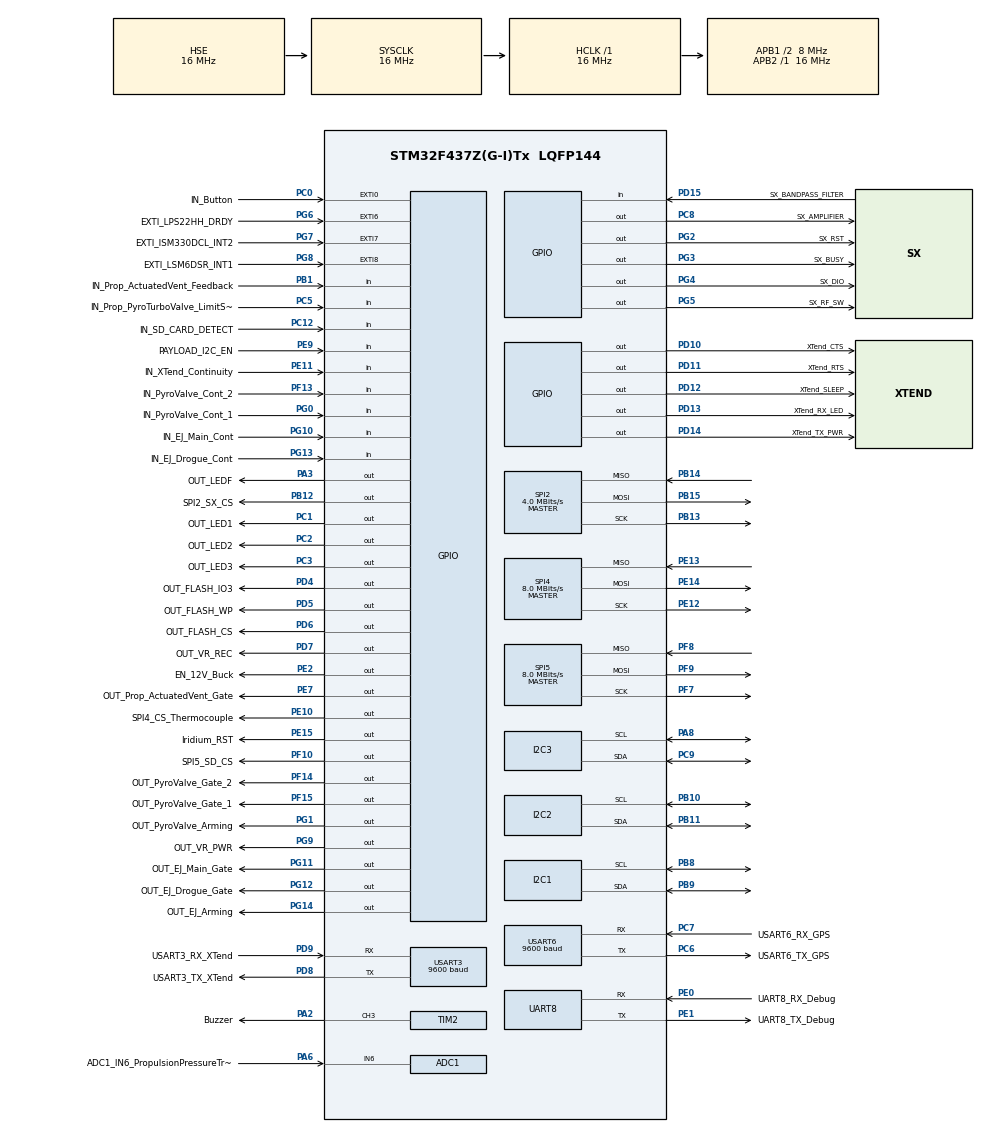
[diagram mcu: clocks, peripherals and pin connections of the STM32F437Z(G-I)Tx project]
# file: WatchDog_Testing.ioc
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ADC1.Channel-0\#ChannelRegularConversion=ADC_CHANNEL_6
ADC1.NbrOfConversionFlag=1
ADC1.Rank-0\#ChannelRegularConversion=1
ADC1.SamplingTime-0\#ChannelRegularConversion=ADC_SAMPLETIME_3CYCLES
ADC1.master=1
FREERTOS.Mutexes01=MEMORY,Dynamic,NULL;TELEMETRY,Dynamic,NULL;SENSOR_POLLING,Dynamic,NULL
FREERTOS.Tasks01=Memory0,48,512,StartMemory0,Default,NULL,Dynamic,NULL,NULL;Ejection1,32,512,StartEjection1,Default,NULL,Dynamic,NULL,NULL;Telemetry2,40,512,StartTelemetry2,Default,NULL,Dynamic,NULL,NULL;Sensors3,24,512,StartSensors3,Default,NULL,Dynamic,NULL,NULL;Propulsion4,48,512,StartPropulsion4,Default,NULL,Dynamic,NULL,NULL;Printing,8,512,StartPrinting,Default,NULL,Dynamic,NULL,NULL
FREERTOS.configUSE_NEWLIB_REENTRANT=1
IWDG.Prescaler=IWDG_PRESCALER_64
IWDG.Reload=2499
Mcu.Family=STM32F4
Mcu.Name=STM32F437Z(G-I)Tx
Mcu.Package=LQFP144
NVIC.EXTI0_IRQn=true\:5\:0\:false\:false\:true\:true\:true\:true
NVIC.PriorityGroup=NVIC_PRIORITYGROUP_4
NVIC.RTC_Alarm_IRQn=true\:5\:0\:false\:false\:true\:false\:true\:true
NVIC.TIM6_DAC_IRQn=true\:0\:0\:false\:false\:true\:false\:false\:true
NVIC.TimeBase=TIM6_DAC_IRQn
NVIC.TimeBaseIP=TIM6
PA13.Mode=Trace_Asynchronous_SW
PA13.Signal=SYS_JTMS-SWDIO
PA14.Mode=Trace_Asynchronous_SW
PA14.Signal=SYS_JTCK-SWCLK
PA2.GPIO_Label=Buzzer
PA2.Signal=S_TIM2_CH3
PA3.GPIO_Label=OUT_LEDF
PA3.Signal=GPIO_Output
PA6.GPIO_Label=ADC1_IN6_PropulsionPressureTransducer
PA6.Signal=ADCx_IN6
PA8.GPIO_Pu=GPIO_PULLUP
PA8.Mode=I2C
PA8.Signal=I2C3_SCL
PB1.GPIO_Label=IN_Prop_ActuatedVent_Feedback
PB1.Signal=GPIO_Input
PB10.GPIO_Pu=GPIO_PULLUP
PB10.Mode=I2C
PB10.Signal=I2C2_SCL
PB11.GPIO_Pu=GPIO_PULLUP
PB11.Mode=I2C
PB11.Signal=I2C2_SDA
PB12.GPIO_Label=SPI2_SX_CS
PB12.Signal=GPIO_Output
PB13.Mode=Full_Duplex_Master
PB13.Signal=SPI2_SCK
PB14.Mode=Full_Duplex_Master
PB14.Signal=SPI2_MISO
PB15.Mode=Full_Duplex_Master
PB15.Signal=SPI2_MOSI
PB3.Mode=Trace_Asynchronous_SW
PB3.Signal=SYS_JTDO-SWO
PB8.GPIO_Pu=GPIO_PULLUP
PB8.Mode=I2C
PB8.Signal=I2C1_SCL
PB9.GPIO_Pu=GPIO_PULLUP
PB9.Mode=I2C
PB9.Signal=I2C1_SDA
PC0.GPIO_Label=IN_Button
PC0.GPIO_ModeDefaultEXTI=GPIO_MODE_IT_FALLING
PC0.Signal=GPXTI0
PC1.GPIO_Label=OUT_LED1
PC1.Signal=GPIO_Output
PC12.GPIO_Label=IN_SD_CARD_DETECT
PC12.Signal=GPIO_Input
PC14/OSC32_IN.Mode=LSE-External-Oscillator
PC14/OSC32_IN.Signal=RCC_OSC32_IN
PC15/OSC32_OUT.Mode=LSE-External-Oscillator
PC15/OSC32_OUT.Signal=RCC_OSC32_OUT
PC2.GPIO_Label=OUT_LED2
PC2.Signal=GPIO_Output
PC3.GPIO_Label=OUT_LED3
PC3.Signal=GPIO_Output
PC5.GPIO_Label=IN_Prop_PyroTurboValve_LimitSwitch
PC5.Signal=GPIO_Input
PC6.GPIO_Label=USART6_TX_GPS
PC6.Mode=Asynchronous
PC6.Signal=USART6_TX
PC7.GPIO_Label=USART6_RX_GPS
PC7.Mode=Asynchronous
PC7.Signal=USART6_RX
PC8.GPIO_Label=SX_AMPLIFIER
PC8.Signal=GPIO_Output
PC9.GPIO_Pu=GPIO_PULLUP
PC9.Mode=I2C
PC9.Signal=I2C3_SDA
PD10.GPIO_Label=XTend_CTS
PD10.Signal=GPIO_Output
PD11.GPIO_Label=XTend_RTS
PD11.Signal=GPIO_Output
PD12.GPIO_Label=XTend_SLEEP
PD12.Signal=GPIO_Output
PD13.GPIO_Label=XTend_RX_LED
PD13.Signal=GPIO_Output
PD14.GPIO_Label=XTend_TX_PWR
PD14.Signal=GPIO_Output
PD15.GPIO_Label=SX_BANDPASS_FILTER
PD15.Signal=GPIO_Input
PD4.GPIO_Label=OUT_FLASH_IO3
PD4.Signal=GPIO_Output
PD5.GPIO_Label=OUT_FLASH_WP
PD5.Signal=GPIO_Output
PD6.GPIO_Label=OUT_FLASH_CS
PD6.Signal=GPIO_Output
PD7.GPIO_Label=OUT_VR_REC
PD7.Signal=GPIO_Output
PD8.GPIO_Label=USART3_TX_XTend
PD8.Mode=Asynchronous
PD8.Signal=USART3_TX
PD9.GPIO_Label=USART3_RX_XTend
PD9.Mode=Asynchronous
PD9.Signal=USART3_RX
PE0.GPIO_Label=UART8_RX_Debug
PE0.Mode=Asynchronous
PE0.Signal=UART8_RX
PE1.GPIO_Label=UART8_TX_Debug
PE1.Mode=Asynchronous
PE1.Signal=UART8_TX
PE10.GPIO_Label=SPI4_CS_Thermocouple
PE10.Signal=GPIO_Output
PE11.GPIO_Label=IN_XTend_Continuity
PE11.Signal=GPIO_Input
PE12.Mode=Full_Duplex_Master
PE12.Signal=SPI4_SCK
PE13.Mode=Full_Duplex_Master
PE13.Signal=SPI4_MISO
PE14.Mode=Full_Duplex_Master
PE14.Signal=SPI4_MOSI
PE15.GPIO_Label=Iridium_RST
PE15.Signal=GPIO_Output
PE2.GPIO_Label=EN_12V_Buck
PE2.Signal=GPIO_Output
PE7.GPIO_Label=OUT_Prop_ActuatedVent_Gate
PE7.Signal=GPIO_Output
PE9.GPIO_Label=PAYLOAD_I2C_EN
PE9.Signal=GPIO_Input
PF10.GPIO_Label=SPI5_SD_CS
PF10.Signal=GPIO_Output
PF13.GPIO_Label=IN_PyroValve_Cont_2
PF13.Signal=GPIO_Input
PF14.GPIO_Label=OUT_PyroValve_Gate_2
PF14.Signal=GPIO_Output
PF15.GPIO_Label=OUT_PyroValve_Gate_1
PF15.Signal=GPIO_Output
PF7.Mode=Full_Duplex_Master
PF7.Signal=SPI5_SCK
PF8.Mode=Full_Duplex_Master
PF8.Signal=SPI5_MISO
PF9.Mode=Full_Duplex_Master
PF9.Signal=SPI5_MOSI
PG0.GPIO_Label=IN_PyroValve_Cont_1
PG0.Signal=GPIO_Input
PG1.GPIO_Label=OUT_PyroValve_Arming
PG1.Signal=GPIO_Output
PG10.GPIO_Label=IN_EJ_Main_Cont
PG10.Signal=GPIO_Input
PG11.GPIO_Label=OUT_EJ_Main_Gate
PG11.Signal=GPIO_Output
PG12.GPIO_Label=OUT_EJ_Drogue_Gate
PG12.Signal=GPIO_Output
PG13.GPIO_Label=IN_EJ_Drogue_Cont
PG13.Signal=GPIO_Input
PG14.GPIO_Label=OUT_EJ_Arming
PG14.Signal=GPIO_Output
PG2.GPIO_Label=SX_RST
PG2.Signal=GPIO_Output
PG3.GPIO_Label=SX_BUSY
PG3.Signal=GPIO_Output
PG4.GPIO_Label=SX_DIO
PG4.Signal=GPIO_Output
PG5.GPIO_Label=SX_RF_SW
PG5.Signal=GPIO_Output
PG6.GPIO_Label=EXTI_LPS22HH_DRDY
PG6.Signal=GPXTI6
PG7.GPIO_Label=EXTI_ISM330DCL_INT2
PG7.Signal=GPXTI7
PG8.GPIO_Label=EXTI_LSM6DSR_INT1
PG8.Signal=GPXTI8
PG9.GPIO_Label=OUT_VR_PWR
PG9.Signal=GPIO_Output
PH0/OSC_IN.Mode=HSE-External-Oscillator
PH0/OSC_IN.Signal=RCC_OSC_IN
PH1/OSC_OUT.Mode=HSE-External-Oscillator
PH1/OSC_OUT.Signal=RCC_OSC_OUT
ProjectManager.HeapSize=0x600
ProjectManager.StackSize=0x400
ProjectManager.TargetToolchain=STM32CubeIDE
RCC.48MHZClocksFreq_Value=48000000
RCC.AHBFreq_Value=16000000
RCC.APB1CLKDivider=RCC_HCLK_DIV2
RCC.APB1Freq_Value=8000000
RCC.APB1TimFreq_Value=16000000
RCC.APB2Freq_Value=16000000
RCC.APB2TimFreq_Value=16000000
RCC.CortexFreq_Value=16000000
RCC.HCLKFreq_Value=16000000
RCC.HSE_VALUE=16000000
RCC.HSI_VALUE=16000000
RCC.PLLM=8
RCC.PLLN=72
RCC.PLLQ=3
RCC.PLLSourceVirtual=RCC_PLLSOURCE_HSE
RCC.SYSCLKFreq_VALUE=16000000
RCC.SYSCLKSource=RCC_SYSCLKSOURCE_HSE
RCC.VCOOutputFreq_Value=144000000
RTC.Alarm=RTC_ALARM_A
RTC.Minutes_A=1
SH.ADCx_IN6.0=ADC1_IN6,IN6
SH.S_TIM2_CH3.0=TIM2_CH3,PWM Generation3 CH3
SPI2.BaudRatePrescaler=SPI_BAUDRATEPRESCALER_2
SPI2.CalculateBaudRate=4.0 MBits/s
SPI2.Direction=SPI_DIRECTION_2LINES
SPI2.Mode=SPI_MODE_MASTER
SPI2.VirtualType=VM_MASTER
SPI4.BaudRatePrescaler=SPI_BAUDRATEPRESCALER_2
SPI4.CalculateBaudRate=8.0 MBits/s
SPI4.Direction=SPI_DIRECTION_2LINES
SPI4.Mode=SPI_MODE_MASTER
SPI4.VirtualType=VM_MASTER
SPI5.BaudRatePrescaler=SPI_BAUDRATEPRESCALER_2
SPI5.CalculateBaudRate=8.0 MBits/s
SPI5.Direction=SPI_DIRECTION_2LINES
SPI5.Mode=SPI_MODE_MASTER
SPI5.VirtualType=VM_MASTER
TIM2.Channel-PWM\ Generation3\ CH3=TIM_CHANNEL_3
UART8.VirtualMode=Asynchronous
USART3.BaudRate=9600
USART3.VirtualMode=VM_ASYNC
USART6.BaudRate=9600
USART6.VirtualMode=VM_ASYNC
VP_FREERTOS_VS_CMSIS_V2.Mode=CMSIS_V2
VP_IWDG_VS_IWDG.Mode=IWDG_Activate
VP_RTC_VS_RTC_Activate.Mode=RTC_Enabled
VP_RTC_VS_RTC_Alarm_A_Intern.Mode=Alarm A
VP_RTC_VS_RTC_Calendar.Mode=RTC_Calendar
VP_SYS_VS_tim6.Mode=TIM6
board=custom

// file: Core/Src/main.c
/* USER CODE BEGIN Header */
/**
  ******************************************************************************
  * @file           : main.c
  * @brief          : Main program body
  ******************************************************************************
  * @attention
  *
  * <h2><center>&copy; Copyright (c) 2022 STMicroelectronics.
  * All rights reserved.</center></h2>
  *
  * This software component is licensed by ST under Ultimate Liberty license
  * SLA0044, the "License"; You may not use this file except in compliance with
  * the License. You may obtain a copy of the License at:
  *                             www.st.com/SLA0044
  *
  ******************************************************************************
  */
/* USER CODE END Header */
#include "main.h"
#include "cmsis_os.h"

/* USER CODE BEGIN Includes */

#include <string.h>
#include <MRT_Helpers.h>

/* USER CODE END Includes */

ADC_HandleTypeDef hadc1;

I2C_HandleTypeDef hi2c1;
I2C_HandleTypeDef hi2c2;
I2C_HandleTypeDef hi2c3;

IWDG_HandleTypeDef hiwdg;

RTC_HandleTypeDef hrtc;

SPI_HandleTypeDef hspi2;
SPI_HandleTypeDef hspi4;
SPI_HandleTypeDef hspi5;

TIM_HandleTypeDef htim2;

UART_HandleTypeDef huart8;
UART_HandleTypeDef huart3;
UART_HandleTypeDef huart6;

/* Definitions for Memory0 */
osThreadId_t Memory0Handle;
const osThreadAttr_t Memory0_attributes = {
  .name = "Memory0",
  .stack_size = 512 * 4,
  .priority = (osPriority_t) osPriorityRealtime,
};
/* Definitions for Ejection1 */
osThreadId_t Ejection1Handle;
const osThreadAttr_t Ejection1_attributes = {
  .name = "Ejection1",
  .stack_size = 512 * 4,
  .priority = (osPriority_t) osPriorityAboveNormal,
};
/* Definitions for Telemetry2 */
osThreadId_t Telemetry2Handle;
const osThreadAttr_t Telemetry2_attributes = {
  .name = "Telemetry2",
  .stack_size = 512 * 4,
  .priority = (osPriority_t) osPriorityHigh,
};
/* Definitions for Sensors3 */
osThreadId_t Sensors3Handle;
const osThreadAttr_t Sensors3_attributes = {
  .name = "Sensors3",
  .stack_size = 512 * 4,
  .priority = (osPriority_t) osPriorityNormal,
};
/* Definitions for Propulsion4 */
osThreadId_t Propulsion4Handle;
const osThreadAttr_t Propulsion4_attributes = {
  .name = "Propulsion4",
  .stack_size = 512 * 4,
  .priority = (osPriority_t) osPriorityRealtime,
};
/* Definitions for Printing */
osThreadId_t PrintingHandle;
const osThreadAttr_t Printing_attributes = {
  .name = "Printing",
  .stack_size = 512 * 4,
  .priority = (osPriority_t) osPriorityLow,
};
/* Definitions for MEMORY */
osMutexId_t MEMORYHandle;
const osMutexAttr_t MEMORY_attributes = {
  .name = "MEMORY"
};
/* Definitions for TELEMETRY */
osMutexId_t TELEMETRYHandle;
const osMutexAttr_t TELEMETRY_attributes = {
  .name = "TELEMETRY"
};
/* Definitions for SENSOR_POLLING */
osMutexId_t SENSOR_POLLINGHandle;
const osMutexAttr_t SENSOR_POLLING_attributes = {
  .name = "SENSOR_POLLING"
};

void SystemClock_Config(void);
static void MX_GPIO_Init(void);
static void MX_ADC1_Init(void);
static void MX_I2C1_Init(void);
static void MX_I2C2_Init(void);
static void MX_I2C3_Init(void);
static void MX_SPI2_Init(void);
static void MX_SPI4_Init(void);
static void MX_SPI5_Init(void);
static void MX_TIM2_Init(void);
static void MX_UART8_Init(void);
static void MX_USART3_UART_Init(void);
static void MX_USART6_UART_Init(void);
static void MX_RTC_Init(void);
static void MX_IWDG_Init(void);
void StartMemory0(void *argument);
void StartEjection1(void *argument);
void StartTelemetry2(void *argument);
void StartSensors3(void *argument);
void StartPropulsion4(void *argument);
void StartPrinting(void *argument);

int main(void)
{

  /* MCU Configuration--------------------------------------------------------*/

  /* Reset of all peripherals, Initializes the Flash interface and the Systick. */
  HAL_Init();

  /* Configure the system clock */
  SystemClock_Config();

  /* Initialize all configured peripherals */
  MX_GPIO_Init();
  MX_ADC1_Init();
  MX_I2C1_Init();
  MX_I2C2_Init();
  MX_I2C3_Init();
  MX_SPI2_Init();
  MX_SPI4_Init();
  MX_SPI5_Init();
  MX_TIM2_Init();
  MX_UART8_Init();
  MX_USART3_UART_Init();
  MX_USART6_UART_Init();
  MX_RTC_Init();
  //MX_IWDG_Init();
  /* USER CODE BEGIN 2 */

  //TODO

#define TX_BUF_DIM 50
char buffer[TX_BUF_DIM];

  //Test external button interrupt
  //Add External Falling Edge Trigger detection to the GPIO and activate NVIC for its line (line0 here)
  //CALL BACK DEFINED IN USE CODE 4 BUT WILL BE INCLUDED INSIDE MRT_HELPERS_f4xx

/*
 * TODO BIG BUG:
 * When activating sprintf and scanf for float AND using FLASH memory on MCU seems to be crashing everything, also sprintf
 * creates an hardfault. When going back to not activated, the values acts weirdly (stays at 0 on each
 * cycle for no reason even though it's supposed to work. When going into
 * debugger mode, the weird behavior disappears.
 *
 * Potential solutions:
 * -Let the init function have a setup delay (DOESN'T WORK)
 * -Add the delay before the init (DOESN'T WORK)
 * -Cast the flags to uint8_t or char before printing
 * -The newlib nano library (the one used when activating sprinf) is the cause of the problem
 */

  //Write to flash Memory

  /* Unlock the Flash Program Erase controller */
/*
  HAL_FLASH_Unlock();

  /* EEPROM Init
  if( EE_Init() != EE_OK)
  {
    Error_Handler();
  }

  MRT_getFlags();
  MRT_resetInfo(&huart8);
  */

char vbuffer[50];
sprintf(vbuffer,"Reset: %i,  WU: %i\r\n",1, 1);
HAL_UART_Transmit(&huart8, vbuffer, strlen(vbuffer), HAL_MAX_DELAY);

  HAL_Delay(2000);

  //Random reset
  NVIC_SystemReset();

  /* USER CODE END 2 */

  /* Init scheduler */
  osKernelInitialize();
  /* Create the mutex(es) */
  /* creation of MEMORY */
  MEMORYHandle = osMutexNew(&MEMORY_attributes);

  /* creation of TELEMETRY */
  TELEMETRYHandle = osMutexNew(&TELEMETRY_attributes);

  /* creation of SENSOR_POLLING */
  SENSOR_POLLINGHandle = osMutexNew(&SENSOR_POLLING_attributes);

  /* Create the thread(s) */
  /* creation of Memory0 */
  Memory0Handle = osThreadNew(StartMemory0, NULL, &Memory0_attributes);

  /* creation of Ejection1 */
  Ejection1Handle = osThreadNew(StartEjection1, NULL, &Ejection1_attributes);

  /* creation of Telemetry2 */
  Telemetry2Handle = osThreadNew(StartTelemetry2, NULL, &Telemetry2_attributes);

  /* creation of Sensors3 */
  Sensors3Handle = osThreadNew(StartSensors3, NULL, &Sensors3_attributes);

  /* creation of Propulsion4 */
  Propulsion4Handle = osThreadNew(StartPropulsion4, NULL, &Propulsion4_attributes);

  /* creation of Printing */
  PrintingHandle = osThreadNew(StartPrinting, NULL, &Printing_attributes);

  /* Start scheduler */
  osKernelStart();

  /* We should never get here as control is now taken by the scheduler */
  /* Infinite loop */
  while (1)
  {

  }
}

void SystemClock_Config(void)
{
  RCC_OscInitTypeDef RCC_OscInitStruct = {0};
  RCC_ClkInitTypeDef RCC_ClkInitStruct = {0};

  /** Configure the main internal regulator output voltage
  */
  __HAL_RCC_PWR_CLK_ENABLE();
  __HAL_PWR_VOLTAGESCALING_CONFIG(PWR_REGULATOR_VOLTAGE_SCALE3);
  /** Initializes the RCC Oscillators according to the specified parameters
  * in the RCC_OscInitTypeDef structure.
  */
  RCC_OscInitStruct.OscillatorType = RCC_OSCILLATORTYPE_LSI|RCC_OSCILLATORTYPE_HSE;
  RCC_OscInitStruct.HSEState = RCC_HSE_ON;
  RCC_OscInitStruct.LSIState = RCC_LSI_ON;
  RCC_OscInitStruct.PLL.PLLState = RCC_PLL_NONE;
  if (HAL_RCC_OscConfig(&RCC_OscInitStruct) != HAL_OK)
  {
    Error_Handler();
  }
  /** Initializes the CPU, AHB and APB buses clocks
  */
  RCC_ClkInitStruct.ClockType = RCC_CLOCKTYPE_HCLK|RCC_CLOCKTYPE_SYSCLK
                              |RCC_CLOCKTYPE_PCLK1|RCC_CLOCKTYPE_PCLK2;
  RCC_ClkInitStruct.SYSCLKSource = RCC_SYSCLKSOURCE_HSE;
  RCC_ClkInitStruct.AHBCLKDivider = RCC_SYSCLK_DIV1;
  RCC_ClkInitStruct.APB1CLKDivider = RCC_HCLK_DIV2;
  RCC_ClkInitStruct.APB2CLKDivider = RCC_HCLK_DIV1;

  if (HAL_RCC_ClockConfig(&RCC_ClkInitStruct, FLASH_LATENCY_0) != HAL_OK)
  {
    Error_Handler();
  }
}

static void MX_ADC1_Init(void)
{

  ADC_ChannelConfTypeDef sConfig = {0};

  /** Configure the global features of the ADC (Clock, Resolution, Data Alignment and number of conversion)
  */
  hadc1.Instance = ADC1;
  hadc1.Init.ClockPrescaler = ADC_CLOCK_SYNC_PCLK_DIV2;
  hadc1.Init.Resolution = ADC_RESOLUTION_12B;
  hadc1.Init.ScanConvMode = DISABLE;
  hadc1.Init.ContinuousConvMode = DISABLE;
  hadc1.Init.DiscontinuousConvMode = DISABLE;
  hadc1.Init.ExternalTrigConvEdge = ADC_EXTERNALTRIGCONVEDGE_NONE;
  hadc1.Init.ExternalTrigConv = ADC_SOFTWARE_START;
  hadc1.Init.DataAlign = ADC_DATAALIGN_RIGHT;
  hadc1.Init.NbrOfConversion = 1;
  hadc1.Init.DMAContinuousRequests = DISABLE;
  hadc1.Init.EOCSelection = ADC_EOC_SINGLE_CONV;
  if (HAL_ADC_Init(&hadc1) != HAL_OK)
  {
    Error_Handler();
  }
  /** Configure for the selected ADC regular channel its corresponding rank in the sequencer and its sample time.
  */
  sConfig.Channel = ADC_CHANNEL_6;
  sConfig.Rank = 1;
  sConfig.SamplingTime = ADC_SAMPLETIME_3CYCLES;
  if (HAL_ADC_ConfigChannel(&hadc1, &sConfig) != HAL_OK)
  {
    Error_Handler();
  }

}

static void MX_I2C1_Init(void)
{

  hi2c1.Instance = I2C1;
  hi2c1.Init.ClockSpeed = 100000;
  hi2c1.Init.DutyCycle = I2C_DUTYCYCLE_2;
  hi2c1.Init.OwnAddress1 = 0;
  hi2c1.Init.AddressingMode = I2C_ADDRESSINGMODE_7BIT;
  hi2c1.Init.DualAddressMode = I2C_DUALADDRESS_DISABLE;
  hi2c1.Init.OwnAddress2 = 0;
  hi2c1.Init.GeneralCallMode = I2C_GENERALCALL_DISABLE;
  hi2c1.Init.NoStretchMode = I2C_NOSTRETCH_DISABLE;
  if (HAL_I2C_Init(&hi2c1) != HAL_OK)
  {
    Error_Handler();
  }
  /** Configure Analogue filter
  */
  if (HAL_I2CEx_ConfigAnalogFilter(&hi2c1, I2C_ANALOGFILTER_ENABLE) != HAL_OK)
  {
    Error_Handler();
  }
  /** Configure Digital filter
  */
  if (HAL_I2CEx_ConfigDigitalFilter(&hi2c1, 0) != HAL_OK)
  {
    Error_Handler();
  }

}

static void MX_I2C2_Init(void)
{

  hi2c2.Instance = I2C2;
  hi2c2.Init.ClockSpeed = 100000;
  hi2c2.Init.DutyCycle = I2C_DUTYCYCLE_2;
  hi2c2.Init.OwnAddress1 = 0;
  hi2c2.Init.AddressingMode = I2C_ADDRESSINGMODE_7BIT;
  hi2c2.Init.DualAddressMode = I2C_DUALADDRESS_DISABLE;
  hi2c2.Init.OwnAddress2 = 0;
  hi2c2.Init.GeneralCallMode = I2C_GENERALCALL_DISABLE;
  hi2c2.Init.NoStretchMode = I2C_NOSTRETCH_DISABLE;
  if (HAL_I2C_Init(&hi2c2) != HAL_OK)
  {
    Error_Handler();
  }
  /** Configure Analogue filter
  */
  if (HAL_I2CEx_ConfigAnalogFilter(&hi2c2, I2C_ANALOGFILTER_ENABLE) != HAL_OK)
  {
    Error_Handler();
  }
  /** Configure Digital filter
  */
  if (HAL_I2CEx_ConfigDigitalFilter(&hi2c2, 0) != HAL_OK)
  {
    Error_Handler();
  }

}

static void MX_I2C3_Init(void)
{

  hi2c3.Instance = I2C3;
  hi2c3.Init.ClockSpeed = 100000;
  hi2c3.Init.DutyCycle = I2C_DUTYCYCLE_2;
  hi2c3.Init.OwnAddress1 = 0;
  hi2c3.Init.AddressingMode = I2C_ADDRESSINGMODE_7BIT;
  hi2c3.Init.DualAddressMode = I2C_DUALADDRESS_DISABLE;
  hi2c3.Init.OwnAddress2 = 0;
  hi2c3.Init.GeneralCallMode = I2C_GENERALCALL_DISABLE;
  hi2c3.Init.NoStretchMode = I2C_NOSTRETCH_DISABLE;
  if (HAL_I2C_Init(&hi2c3) != HAL_OK)
  {
    Error_Handler();
  }
  /** Configure Analogue filter
  */
  if (HAL_I2CEx_ConfigAnalogFilter(&hi2c3, I2C_ANALOGFILTER_ENABLE) != HAL_OK)
  {
    Error_Handler();
  }
  /** Configure Digital filter
  */
  if (HAL_I2CEx_ConfigDigitalFilter(&hi2c3, 0) != HAL_OK)
  {
    Error_Handler();
  }

}

static void MX_IWDG_Init(void)
{

  hiwdg.Instance = IWDG;
  hiwdg.Init.Prescaler = IWDG_PRESCALER_64;
  hiwdg.Init.Reload = 2499;
  if (HAL_IWDG_Init(&hiwdg) != HAL_OK)
  {
    Error_Handler();
  }

}

static void MX_RTC_Init(void)
{

  RTC_TimeTypeDef sTime = {0};
  RTC_DateTypeDef sDate = {0};
  RTC_AlarmTypeDef sAlarm = {0};

  /** Initialize RTC Only
  */
  hrtc.Instance = RTC;
  hrtc.Init.HourFormat = RTC_HOURFORMAT_24;
  hrtc.Init.AsynchPrediv = 127;
  hrtc.Init.SynchPrediv = 255;
  hrtc.Init.OutPut = RTC_OUTPUT_DISABLE;
  hrtc.Init.OutPutPolarity = RTC_OUTPUT_POLARITY_HIGH;
  hrtc.Init.OutPutType = RTC_OUTPUT_TYPE_OPENDRAIN;
  if (HAL_RTC_Init(&hrtc) != HAL_OK)
  {
    Error_Handler();
  }

  /** Initialize RTC and set the Time and Date
  */
  sTime.Hours = 0x0;
  sTime.Minutes = 0x0;
  sTime.Seconds = 0x0;
  sTime.DayLightSaving = RTC_DAYLIGHTSAVING_NONE;
  sTime.StoreOperation = RTC_STOREOPERATION_RESET;
  if (HAL_RTC_SetTime(&hrtc, &sTime, RTC_FORMAT_BCD) != HAL_OK)
  {
    Error_Handler();
  }
  sDate.WeekDay = RTC_WEEKDAY_MONDAY;
  sDate.Month = RTC_MONTH_JANUARY;
  sDate.Date = 0x1;
  sDate.Year = 0x0;

  if (HAL_RTC_SetDate(&hrtc, &sDate, RTC_FORMAT_BCD) != HAL_OK)
  {
    Error_Handler();
  }
  /** Enable the Alarm A
  */
  sAlarm.AlarmTime.Hours = 0x0;
  sAlarm.AlarmTime.Minutes = 0x1;
  sAlarm.AlarmTime.Seconds = 0x0;
  sAlarm.AlarmTime.SubSeconds = 0x0;
  sAlarm.AlarmTime.DayLightSaving = RTC_DAYLIGHTSAVING_NONE;
  sAlarm.AlarmTime.StoreOperation = RTC_STOREOPERATION_RESET;
  sAlarm.AlarmMask = RTC_ALARMMASK_NONE;
  sAlarm.AlarmSubSecondMask = RTC_ALARMSUBSECONDMASK_ALL;
  sAlarm.AlarmDateWeekDaySel = RTC_ALARMDATEWEEKDAYSEL_DATE;
  sAlarm.AlarmDateWeekDay = 0x1;
  sAlarm.Alarm = RTC_ALARM_A;
  if (HAL_RTC_SetAlarm_IT(&hrtc, &sAlarm, RTC_FORMAT_BCD) != HAL_OK)
  {
    Error_Handler();
  }

}

static void MX_SPI2_Init(void)
{

  /* SPI2 parameter configuration*/
  hspi2.Instance = SPI2;
  hspi2.Init.Mode = SPI_MODE_MASTER;
  hspi2.Init.Direction = SPI_DIRECTION_2LINES;
  hspi2.Init.DataSize = SPI_DATASIZE_8BIT;
  hspi2.Init.CLKPolarity = SPI_POLARITY_LOW;
  hspi2.Init.CLKPhase = SPI_PHASE_1EDGE;
  hspi2.Init.NSS = SPI_NSS_SOFT;
  hspi2.Init.BaudRatePrescaler = SPI_BAUDRATEPRESCALER_2;
  hspi2.Init.FirstBit = SPI_FIRSTBIT_MSB;
  hspi2.Init.TIMode = SPI_TIMODE_DISABLE;
  hspi2.Init.CRCCalculation = SPI_CRCCALCULATION_DISABLE;
  hspi2.Init.CRCPolynomial = 10;
  if (HAL_SPI_Init(&hspi2) != HAL_OK)
  {
    Error_Handler();
  }

}

static void MX_SPI4_Init(void)
{

  /* SPI4 parameter configuration*/
  hspi4.Instance = SPI4;
  hspi4.Init.Mode = SPI_MODE_MASTER;
  hspi4.Init.Direction = SPI_DIRECTION_2LINES;
  hspi4.Init.DataSize = SPI_DATASIZE_8BIT;
  hspi4.Init.CLKPolarity = SPI_POLARITY_LOW;
  hspi4.Init.CLKPhase = SPI_PHASE_1EDGE;
  hspi4.Init.NSS = SPI_NSS_SOFT;
  hspi4.Init.BaudRatePrescaler = SPI_BAUDRATEPRESCALER_2;
  hspi4.Init.FirstBit = SPI_FIRSTBIT_MSB;
  hspi4.Init.TIMode = SPI_TIMODE_DISABLE;
  hspi4.Init.CRCCalculation = SPI_CRCCALCULATION_DISABLE;
  hspi4.Init.CRCPolynomial = 10;
  if (HAL_SPI_Init(&hspi4) != HAL_OK)
  {
    Error_Handler();
  }

}

static void MX_SPI5_Init(void)
{

  /* SPI5 parameter configuration*/
  hspi5.Instance = SPI5;
  hspi5.Init.Mode = SPI_MODE_MASTER;
  hspi5.Init.Direction = SPI_DIRECTION_2LINES;
  hspi5.Init.DataSize = SPI_DATASIZE_8BIT;
  hspi5.Init.CLKPolarity = SPI_POLARITY_LOW;
  hspi5.Init.CLKPhase = SPI_PHASE_1EDGE;
  hspi5.Init.NSS = SPI_NSS_SOFT;
  hspi5.Init.BaudRatePrescaler = SPI_BAUDRATEPRESCALER_2;
  hspi5.Init.FirstBit = SPI_FIRSTBIT_MSB;
  hspi5.Init.TIMode = SPI_TIMODE_DISABLE;
  hspi5.Init.CRCCalculation = SPI_CRCCALCULATION_DISABLE;
  hspi5.Init.CRCPolynomial = 10;
  if (HAL_SPI_Init(&hspi5) != HAL_OK)
  {
    Error_Handler();
  }

}

static void MX_TIM2_Init(void)
{

  TIM_MasterConfigTypeDef sMasterConfig = {0};
  TIM_OC_InitTypeDef sConfigOC = {0};

  htim2.Instance = TIM2;
  htim2.Init.Prescaler = 0;
  htim2.Init.CounterMode = TIM_COUNTERMODE_UP;
  htim2.Init.Period = 4294967295;
  htim2.Init.ClockDivision = TIM_CLOCKDIVISION_DIV1;
  htim2.Init.AutoReloadPreload = TIM_AUTORELOAD_PRELOAD_DISABLE;
  if (HAL_TIM_PWM_Init(&htim2) != HAL_OK)
  {
    Error_Handler();
  }
  sMasterConfig.MasterOutputTrigger = TIM_TRGO_RESET;
  sMasterConfig.MasterSlaveMode = TIM_MASTERSLAVEMODE_DISABLE;
  if (HAL_TIMEx_MasterConfigSynchronization(&htim2, &sMasterConfig) != HAL_OK)
  {
    Error_Handler();
  }
  sConfigOC.OCMode = TIM_OCMODE_PWM1;
  sConfigOC.Pulse = 0;
  sConfigOC.OCPolarity = TIM_OCPOLARITY_HIGH;
  sConfigOC.OCFastMode = TIM_OCFAST_DISABLE;
  if (HAL_TIM_PWM_ConfigChannel(&htim2, &sConfigOC, TIM_CHANNEL_3) != HAL_OK)
  {
    Error_Handler();
  }
  HAL_TIM_MspPostInit(&htim2);

}

static void MX_UART8_Init(void)
{

  huart8.Instance = UART8;
  huart8.Init.BaudRate = 115200;
  huart8.Init.WordLength = UART_WORDLENGTH_8B;
  huart8.Init.StopBits = UART_STOPBITS_1;
  huart8.Init.Parity = UART_PARITY_NONE;
  huart8.Init.Mode = UART_MODE_TX_RX;
  huart8.Init.HwFlowCtl = UART_HWCONTROL_NONE;
  huart8.Init.OverSampling = UART_OVERSAMPLING_16;
  if (HAL_UART_Init(&huart8) != HAL_OK)
  {
    Error_Handler();
  }

}

static void MX_USART3_UART_Init(void)
{

  huart3.Instance = USART3;
  huart3.Init.BaudRate = 9600;
  huart3.Init.WordLength = UART_WORDLENGTH_8B;
  huart3.Init.StopBits = UART_STOPBITS_1;
  huart3.Init.Parity = UART_PARITY_NONE;
  huart3.Init.Mode = UART_MODE_TX_RX;
  huart3.Init.HwFlowCtl = UART_HWCONTROL_NONE;
  huart3.Init.OverSampling = UART_OVERSAMPLING_16;
  if (HAL_UART_Init(&huart3) != HAL_OK)
  {
    Error_Handler();
  }

}

static void MX_USART6_UART_Init(void)
{

  huart6.Instance = USART6;
  huart6.Init.BaudRate = 9600;
  huart6.Init.WordLength = UART_WORDLENGTH_8B;
  huart6.Init.StopBits = UART_STOPBITS_1;
  huart6.Init.Parity = UART_PARITY_NONE;
  huart6.Init.Mode = UART_MODE_TX_RX;
  huart6.Init.HwFlowCtl = UART_HWCONTROL_NONE;
  huart6.Init.OverSampling = UART_OVERSAMPLING_16;
  if (HAL_UART_Init(&huart6) != HAL_OK)
  {
    Error_Handler();
  }

}

static void MX_GPIO_Init(void)
{
  GPIO_InitTypeDef GPIO_InitStruct = {0};

  /* GPIO Ports Clock Enable */
  __HAL_RCC_GPIOE_CLK_ENABLE();
  __HAL_RCC_GPIOC_CLK_ENABLE();
  __HAL_RCC_GPIOF_CLK_ENABLE();
  __HAL_RCC_GPIOH_CLK_ENABLE();
  __HAL_RCC_GPIOA_CLK_ENABLE();
  __HAL_RCC_GPIOB_CLK_ENABLE();
  __HAL_RCC_GPIOG_CLK_ENABLE();
  __HAL_RCC_GPIOD_CLK_ENABLE();

  /*Configure GPIO pin Output Level */
  HAL_GPIO_WritePin(GPIOE, EN_12V_Buck_Pin|OUT_Prop_ActuatedVent_Gate_Pin|SPI4_CS_Thermocouple_Pin|Iridium_RST_Pin, GPIO_PIN_RESET);

  /*Configure GPIO pin Output Level */
  HAL_GPIO_WritePin(GPIOF, SPI5_SD_CS_Pin|OUT_PyroValve_Gate_2_Pin|OUT_PyroValve_Gate_1_Pin, GPIO_PIN_RESET);

  /*Configure GPIO pin Output Level */
  HAL_GPIO_WritePin(GPIOC, OUT_LED1_Pin|OUT_LED2_Pin|OUT_LED3_Pin|SX_AMPLIFIER_Pin, GPIO_PIN_RESET);

  /*Configure GPIO pin Output Level */
  HAL_GPIO_WritePin(OUT_LEDF_GPIO_Port, OUT_LEDF_Pin, GPIO_PIN_RESET);

  /*Configure GPIO pin Output Level */
  HAL_GPIO_WritePin(GPIOG, OUT_PyroValve_Arming_Pin|SX_RST_Pin|SX_BUSY_Pin|SX_DIO_Pin
                          |SX_RF_SW_Pin|OUT_VR_PWR_Pin|OUT_EJ_Main_Gate_Pin|OUT_EJ_Drogue_Gate_Pin
                          |OUT_EJ_Arming_Pin, GPIO_PIN_RESET);

  /*Configure GPIO pin Output Level */
  HAL_GPIO_WritePin(SPI2_SX_CS_GPIO_Port, SPI2_SX_CS_Pin, GPIO_PIN_RESET);

  /*Configure GPIO pin Output Level */
  HAL_GPIO_WritePin(GPIOD, XTend_CTS_Pin|XTend_RTS_Pin|XTend_SLEEP_Pin|XTend_RX_LED_Pin
                          |XTend_TX_PWR_Pin|OUT_FLASH_IO3_Pin|OUT_FLASH_WP_Pin|OUT_FLASH_CS_Pin
                          |OUT_VR_REC_Pin, GPIO_PIN_RESET);

  /*Configure GPIO pins : EN_12V_Buck_Pin OUT_Prop_ActuatedVent_Gate_Pin SPI4_CS_Thermocouple_Pin Iridium_RST_Pin */
  GPIO_InitStruct.Pin = EN_12V_Buck_Pin|OUT_Prop_ActuatedVent_Gate_Pin|SPI4_CS_Thermocouple_Pin|Iridium_RST_Pin;
  GPIO_InitStruct.Mode = GPIO_MODE_OUTPUT_PP;
  GPIO_InitStruct.Pull = GPIO_NOPULL;
  GPIO_InitStruct.Speed = GPIO_SPEED_FREQ_LOW;
  HAL_GPIO_Init(GPIOE, &GPIO_InitStruct);

  /*Configure GPIO pins : SPI5_SD_CS_Pin OUT_PyroValve_Gate_2_Pin OUT_PyroValve_Gate_1_Pin */
  GPIO_InitStruct.Pin = SPI5_SD_CS_Pin|OUT_PyroValve_Gate_2_Pin|OUT_PyroValve_Gate_1_Pin;
  GPIO_InitStruct.Mode = GPIO_MODE_OUTPUT_PP;
  GPIO_InitStruct.Pull = GPIO_NOPULL;
  GPIO_InitStruct.Speed = GPIO_SPEED_FREQ_LOW;
  HAL_GPIO_Init(GPIOF, &GPIO_InitStruct);

  /*Configure GPIO pin : IN_Button_Pin */
  GPIO_InitStruct.Pin = IN_Button_Pin;
  GPIO_InitStruct.Mode = GPIO_MODE_IT_FALLING;
  GPIO_InitStruct.Pull = GPIO_NOPULL;
  HAL_GPIO_Init(IN_Button_GPIO_Port, &GPIO_InitStruct);

  /*Configure GPIO pins : OUT_LED1_Pin OUT_LED2_Pin OUT_LED3_Pin SX_AMPLIFIER_Pin */
  GPIO_InitStruct.Pin = OUT_LED1_Pin|OUT_LED2_Pin|OUT_LED3_Pin|SX_AMPLIFIER_Pin;
  GPIO_InitStruct.Mode = GPIO_MODE_OUTPUT_PP;
  GPIO_InitStruct.Pull = GPIO_NOPULL;
  GPIO_InitStruct.Speed = GPIO_SPEED_FREQ_LOW;
  HAL_GPIO_Init(GPIOC, &GPIO_InitStruct);

  /*Configure GPIO pin : OUT_LEDF_Pin */
  GPIO_InitStruct.Pin = OUT_LEDF_Pin;
  GPIO_InitStruct.Mode = GPIO_MODE_OUTPUT_PP;
  GPIO_InitStruct.Pull = GPIO_NOPULL;
  GPIO_InitStruct.Speed = GPIO_SPEED_FREQ_LOW;
  HAL_GPIO_Init(OUT_LEDF_GPIO_Port, &GPIO_InitStruct);

  /*Configure GPIO pins : IN_Prop_PyroTurboValve_LimitSwitch_Pin IN_SD_CARD_DETECT_Pin */
  GPIO_InitStruct.Pin = IN_Prop_PyroTurboValve_LimitSwitch_Pin|IN_SD_CARD_DETECT_Pin;
  GPIO_InitStruct.Mode = GPIO_MODE_INPUT;
  GPIO_InitStruct.Pull = GPIO_NOPULL;
  HAL_GPIO_Init(GPIOC, &GPIO_InitStruct);

  /*Configure GPIO pin : IN_Prop_ActuatedVent_Feedback_Pin */
  GPIO_InitStruct.Pin = IN_Prop_ActuatedVent_Feedback_Pin;
  GPIO_InitStruct.Mode = GPIO_MODE_INPUT;
  GPIO_InitStruct.Pull = GPIO_NOPULL;
  HAL_GPIO_Init(IN_Prop_ActuatedVent_Feedback_GPIO_Port, &GPIO_InitStruct);

  /*Configure GPIO pin : IN_PyroValve_Cont_2_Pin */
  GPIO_InitStruct.Pin = IN_PyroValve_Cont_2_Pin;
  GPIO_InitStruct.Mode = GPIO_MODE_INPUT;
  GPIO_InitStruct.Pull = GPIO_NOPULL;
  HAL_GPIO_Init(IN_PyroValve_Cont_2_GPIO_Port, &GPIO_InitStruct);

  /*Configure GPIO pins : IN_PyroValve_Cont_1_Pin IN_EJ_Main_Cont_Pin IN_EJ_Drogue_Cont_Pin */
  GPIO_InitStruct.Pin = IN_PyroValve_Cont_1_Pin|IN_EJ_Main_Cont_Pin|IN_EJ_Drogue_Cont_Pin;
  GPIO_InitStruct.Mode = GPIO_MODE_INPUT;
  GPIO_InitStruct.Pull = GPIO_NOPULL;
  HAL_GPIO_Init(GPIOG, &GPIO_InitStruct);

  /*Configure GPIO pins : OUT_PyroValve_Arming_Pin SX_RST_Pin SX_BUSY_Pin SX_DIO_Pin
                           SX_RF_SW_Pin OUT_VR_PWR_Pin OUT_EJ_Main_Gate_Pin OUT_EJ_Drogue_Gate_Pin
                           OUT_EJ_Arming_Pin */
  GPIO_InitStruct.Pin = OUT_PyroValve_Arming_Pin|SX_RST_Pin|SX_BUSY_Pin|SX_DIO_Pin
                          |SX_RF_SW_Pin|OUT_VR_PWR_Pin|OUT_EJ_Main_Gate_Pin|OUT_EJ_Drogue_Gate_Pin
                          |OUT_EJ_Arming_Pin;
  GPIO_InitStruct.Mode = GPIO_MODE_OUTPUT_PP;
  GPIO_InitStruct.Pull = GPIO_NOPULL;
  GPIO_InitStruct.Speed = GPIO_SPEED_FREQ_LOW;
  HAL_GPIO_Init(GPIOG, &GPIO_InitStruct);

  /*Configure GPIO pins : PAYLOAD_I2C_EN_Pin IN_XTend_Continuity_Pin */
  GPIO_InitStruct.Pin = PAYLOAD_I2C_EN_Pin|IN_XTend_Continuity_Pin;
  GPIO_InitStruct.Mode = GPIO_MODE_INPUT;
  GPIO_InitStruct.Pull = GPIO_NOPULL;
  HAL_GPIO_Init(GPIOE, &GPIO_InitStruct);

  /*Configure GPIO pin : SPI2_SX_CS_Pin */
  GPIO_InitStruct.Pin = SPI2_SX_CS_Pin;
  GPIO_InitStruct.Mode = GPIO_MODE_OUTPUT_PP;
  GPIO_InitStruct.Pull = GPIO_NOPULL;
  GPIO_InitStruct.Speed = GPIO_SPEED_FREQ_LOW;
  HAL_GPIO_Init(SPI2_SX_CS_GPIO_Port, &GPIO_InitStruct);

  /*Configure GPIO pins : XTend_CTS_Pin XTend_RTS_Pin XTend_SLEEP_Pin XTend_RX_LED_Pin
                           XTend_TX_PWR_Pin OUT_FLASH_IO3_Pin OUT_FLASH_WP_Pin OUT_FLASH_CS_Pin
                           OUT_VR_REC_Pin */
  GPIO_InitStruct.Pin = XTend_CTS_Pin|XTend_RTS_Pin|XTend_SLEEP_Pin|XTend_RX_LED_Pin
                          |XTend_TX_PWR_Pin|OUT_FLASH_IO3_Pin|OUT_FLASH_WP_Pin|OUT_FLASH_CS_Pin
                          |OUT_VR_REC_Pin;
  GPIO_InitStruct.Mode = GPIO_MODE_OUTPUT_PP;
  GPIO_InitStruct.Pull = GPIO_NOPULL;
  GPIO_InitStruct.Speed = GPIO_SPEED_FREQ_LOW;
  HAL_GPIO_Init(GPIOD, &GPIO_InitStruct);

  /*Configure GPIO pin : SX_BANDPASS_FILTER_Pin */
  GPIO_InitStruct.Pin = SX_BANDPASS_FILTER_Pin;
  GPIO_InitStruct.Mode = GPIO_MODE_INPUT;
  GPIO_InitStruct.Pull = GPIO_NOPULL;
  HAL_GPIO_Init(SX_BANDPASS_FILTER_GPIO_Port, &GPIO_InitStruct);

  /*Configure GPIO pins : EXTI_LPS22HH_DRDY_Pin EXTI_ISM330DCL_INT2_Pin EXTI_LSM6DSR_INT1_Pin */
  GPIO_InitStruct.Pin = EXTI_LPS22HH_DRDY_Pin|EXTI_ISM330DCL_INT2_Pin|EXTI_LSM6DSR_INT1_Pin;
  GPIO_InitStruct.Mode = GPIO_MODE_IT_RISING;
  GPIO_InitStruct.Pull = GPIO_NOPULL;
  HAL_GPIO_Init(GPIOG, &GPIO_InitStruct);

  /* EXTI interrupt init*/
  HAL_NVIC_SetPriority(EXTI0_IRQn, 5, 0);
  HAL_NVIC_EnableIRQ(EXTI0_IRQn);

}

void StartMemory0(void *argument)
{
  for(;;)
  {
    osDelay(1);
  }
}

void StartEjection1(void *argument)
{
  for(;;)
  {
    osDelay(1);
  }
}

void StartTelemetry2(void *argument)
{
  for(;;)
  {
    osDelay(1);
  }
}

void StartSensors3(void *argument)
{
  for(;;)
  {
    osDelay(1);
  }
}

void StartPropulsion4(void *argument)
{
  for(;;)
  {
    osDelay(1);
  }
}

void StartPrinting(void *argument)
{
  for(;;)
  {
    osDelay(1);
  }
}

void HAL_TIM_PeriodElapsedCallback(TIM_HandleTypeDef *htim)
{
  if (htim->Instance == TIM6) {
    HAL_IncTick();
  }
}

void Error_Handler(void)
{
  __disable_irq();
  while (1)
  {
  }
}

/************************ (C) COPYRIGHT STMicroelectronics *****END OF FILE****/
